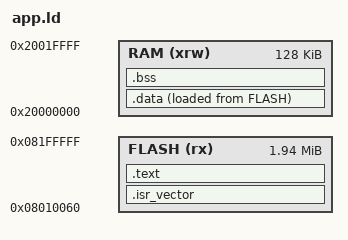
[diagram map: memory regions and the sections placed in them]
/*
 * Linker script for Application, STM32H743ZI.
 * App starts at 0x08010000: first 96 bytes are image_header_t (written by sign script),
 * then .isr_vector and .text at 0x08010060.
 */
OUTPUT_FORMAT("elf32-littlearm")
OUTPUT_ARCH(arm)
ENTRY(Reset_Handler)

MEMORY
{
    FLASH (rx)  : ORIGIN = 0x08010060, LENGTH = 2048K - 64K - 96
    RAM   (xrw) : ORIGIN = 0x20000000, LENGTH = 128K
}

_estack = ORIGIN(RAM) + LENGTH(RAM);

SECTIONS
{
    .isr_vector :
    {
        . = ALIGN(128);   /* VTOR requires 128-byte aligned vector table */
        KEEP(*(.isr_vector))
        . = ALIGN(4);
    } > FLASH

    .text :
    {
        . = ALIGN(4);
        *(.text)
        *(.text*)
        *(.rodata)
        *(.rodata*)
        . = ALIGN(4);
        _etext = .;
    } > FLASH

    .data :
    {
        . = ALIGN(4);
        _sdata = .;
        *(.data)
        *(.data*)
        . = ALIGN(4);
        _edata = .;
    } > RAM AT > FLASH
    _sidata = LOADADDR(.data);

    .bss :
    {
        . = ALIGN(4);
        _sbss = .;
        *(.bss)
        *(.bss*)
        *(COMMON)
        . = ALIGN(4);
        _ebss = .;
        _end = .;
    } > RAM
}
